# MB9AF15xR register map
File version: 1.7
Registers are 32-bit, read-write, reset 0x0 unless marked. A register's access mark holds for its fields unless they carry their own. Offsets are from the block's base; [hi:lo] are bit positions; {n}, {i} and the like mark numbered series; 'fields as' and 'values as' point back to an identical list.

## GPIO — General-purpose I/O ports
Base 0x40033000
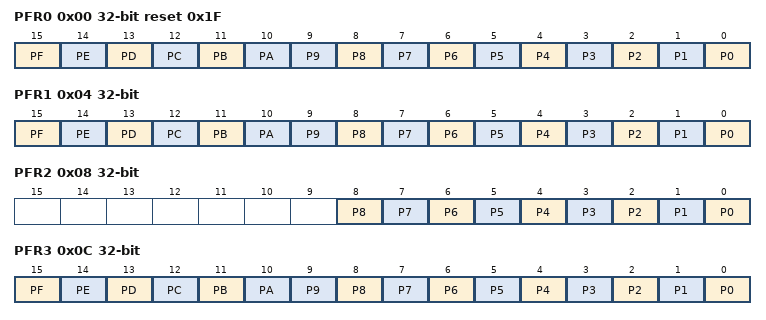
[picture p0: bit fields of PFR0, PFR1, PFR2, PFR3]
0x00 PFR0 reset 0x1F — Port function setting register 0
  [15] PF — Bit15 of PFR0
  [14] PE — Bit14 of PFR0
  [13] PD — Bit13 of PFR0
  [12] PC — Bit12 of PFR0
  [11] PB — Bit11 of PFR0
  [10] PA — Bit10 of PFR0
  [n] P{n} (n=0..9) — Bit{n} of PFR0
0x04 PFR1 — Port function setting register 1
  [15] PF — Bit15 of PFR1
  [14] PE — Bit14 of PFR1
  [13] PD — Bit13 of PFR1
  [12] PC — Bit12 of PFR1
  [11] PB — Bit11 of PFR1
  [10] PA — Bit10 of PFR1
  [n] P{n} (n=0..9) — Bit{n} of PFR1
0x08 PFR2 — Port function setting register 2
  [n] P{n} (n=0..8) — Bit{n} of PFR2
0x0C PFR3 — Port function setting register 3
  [15] PF — Bit15 of PFR3
  [14] PE — Bit14 of PFR3
  [13] PD — Bit13 of PFR3
  [12] PC — Bit12 of PFR3
  [11] PB — Bit11 of PFR3
  [10] PA — Bit10 of PFR3
  [n] P{n} (n=0..9) — Bit{n} of PFR3
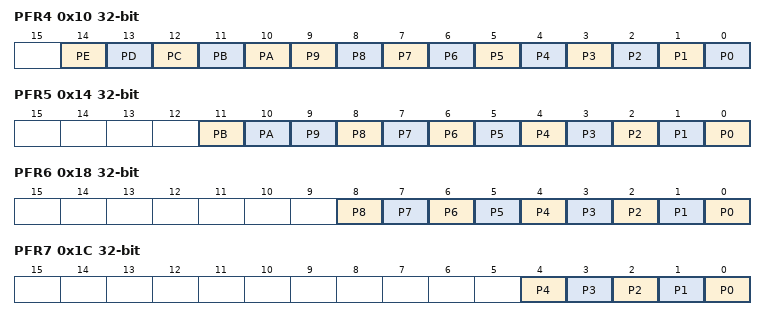
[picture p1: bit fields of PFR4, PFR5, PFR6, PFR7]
0x10 PFR4 — Port function setting register 4
  [14] PE — Bit14 of PFR4
  [13] PD — Bit13 of PFR4
  [12] PC — Bit12 of PFR4
  [11] PB — Bit11 of PFR4
  [10] PA — Bit10 of PFR4
  [n] P{n} (n=0..9) — Bit{n} of PFR4
0x14 PFR5 — Port function setting register 5
  [11] PB — Bit11 of PFR5
  [10] PA — Bit10 of PFR5
  [n] P{n} (n=0..9) — Bit{n} of PFR5
0x18 PFR6 — Port function setting register 6
  [n] P{n} (n=0..8) — Bit{n} of PFR6
0x1C PFR7 — Port function setting register 7
  [n] P{n} (n=0..4) — Bit{n} of PFR6
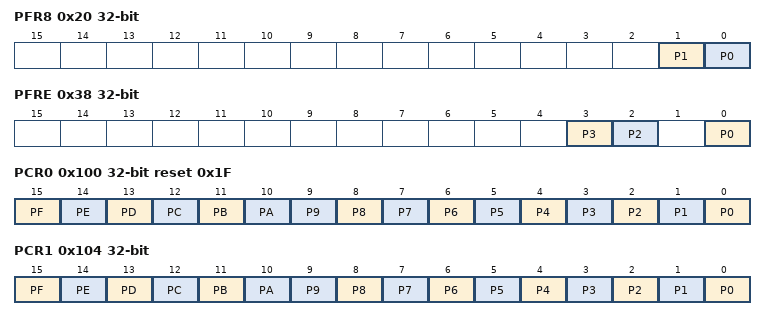
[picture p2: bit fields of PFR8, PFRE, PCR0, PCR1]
0x20 PFR8 — Port function setting register 8
  [1] P1 — Bit1 of PFR8
  [0] P0 — Bit0 of PFR8
0x38 PFRE — Port function setting register E
  [3] P3 — Bit3 of PFRE
  [2] P2 — Bit2 of PFRE
  [0] P0 — Bit0 of PFRE
0x100 PCR0 reset 0x1F — Pull-up Setting Register 0
  fields as PFR0
0x104 PCR1 — Pull-up Setting Register 1
  fields as PFR1
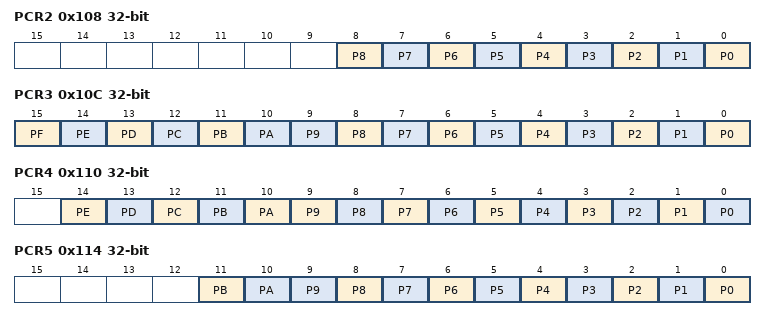
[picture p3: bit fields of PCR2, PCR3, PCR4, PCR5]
0x108 PCR2 — Pull-up Setting Register 2
  [n] P{n} (n=0..8) — Bit{n} of PFR2
0x10C PCR3 — Pull-up Setting Register 3
  fields as PFR3
0x110 PCR4 — Pull-up Setting Register 4
  fields as PFR4
0x114 PCR5 — Pull-up Setting Register 5
  fields as PFR5
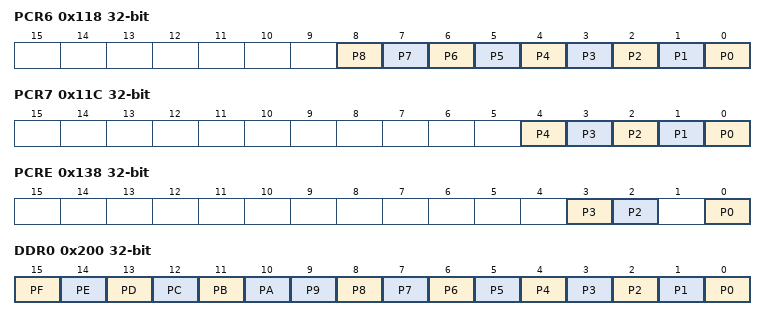
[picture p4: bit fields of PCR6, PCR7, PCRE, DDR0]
0x118 PCR6 — Pull-up Setting Register 6
  [n] P{n} (n=0..8) — Bit{n} of PFR6
0x11C PCR7 — Pull-up Setting Register 7
  [n] P{n} (n=0..4) — Bit{n} of PFR6
0x138 PCRE — Pull-up Setting Register E
  fields as PFRE
0x200 DDR0 — Port input/output direction setting register 0
  [15] PF — Bit15 of DDR0
  [14] PE — Bit14 of DDR0
  [13] PD — Bit13 of DDR0
  [12] PC — Bit12 of DDR0
  [11] PB — Bit11 of DDR0
  [10] PA — Bit10 of DDR0
  [n] P{n} (n=0..9) — Bit{n} of DDR0
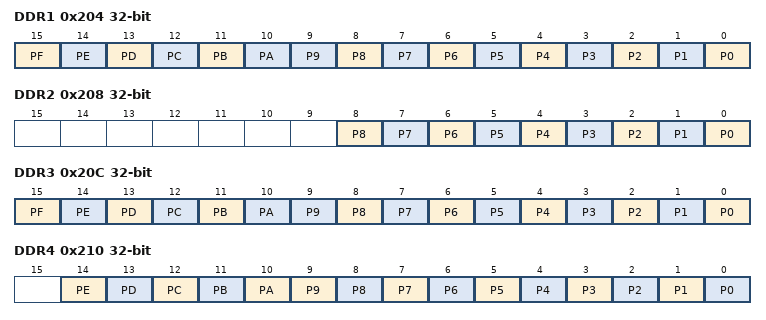
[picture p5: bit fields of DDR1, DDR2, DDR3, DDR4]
0x204 DDR1 — Port input/output direction setting register 1
  fields as PFR1
0x208 DDR2 — Port input/output direction setting register 2
  [n] P{n} (n=0..8) — Bit{n} of PFR2
0x20C DDR3 — Port input/output direction setting register 3
  fields as PFR3
0x210 DDR4 — Port input/output direction setting register 4
  fields as PFR4
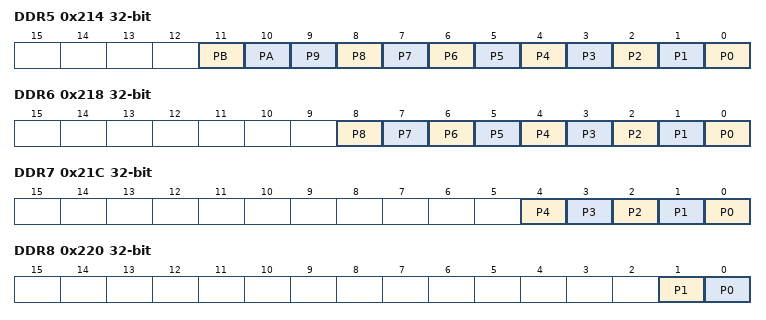
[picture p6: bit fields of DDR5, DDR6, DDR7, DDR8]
0x214 DDR5 — Port input/output direction setting register 5
  fields as PFR5
0x218 DDR6 — Port input/output direction setting register 6
  [n] P{n} (n=0..8) — Bit{n} of PFR6
0x21C DDR7 — Port input/output direction setting register 7
  [n] P{n} (n=0..4) — Bit{n} of PFR6
0x220 DDR8 — Port input/output direction setting register 8
  [1] P1 — Bit1 of PFR8
  [0] P0 — Bit0 of PFR8
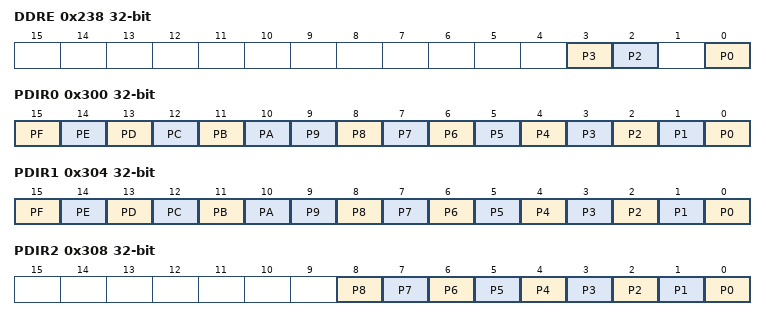
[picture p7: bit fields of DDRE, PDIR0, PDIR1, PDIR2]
0x238 DDRE — Port input/output direction setting register E
  fields as PFRE
0x300 PDIR0 — Port input data register 0
  fields as DDR0
0x304 PDIR1 — Port input data register 1
  fields as PFR1
0x308 PDIR2 — Port input data register 2
  [n] P{n} (n=0..8) — Bit{n} of PFR2
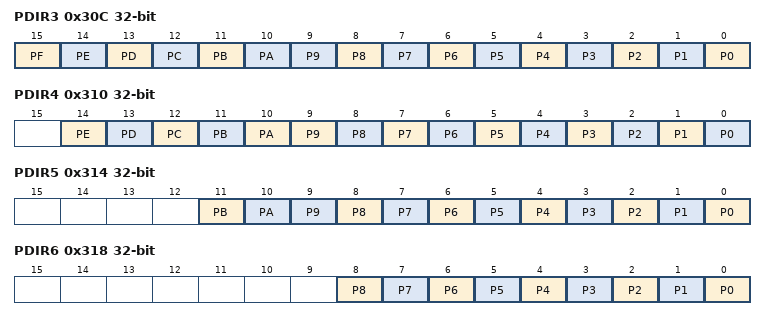
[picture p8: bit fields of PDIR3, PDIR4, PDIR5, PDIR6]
0x30C PDIR3 — Port input data register 3
  fields as PFR3
0x310 PDIR4 — Port input data register 4
  fields as PFR4
0x314 PDIR5 — Port input data register 5
  fields as PFR5
0x318 PDIR6 — Port input data register 6
  [n] P{n} (n=0..8) — Bit{n} of PFR6
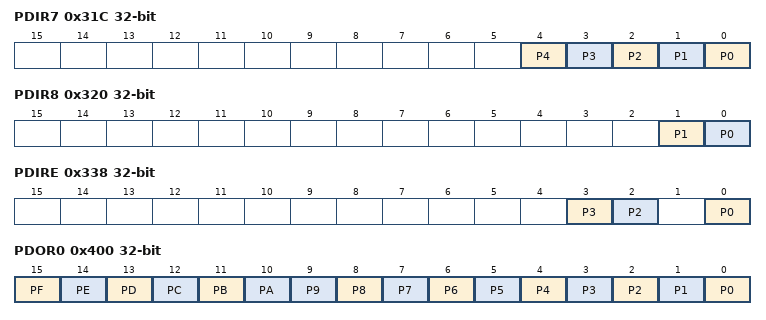
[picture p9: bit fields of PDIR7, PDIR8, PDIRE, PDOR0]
0x31C PDIR7 — Port input data register 7
  [n] P{n} (n=0..4) — Bit{n} of PFR6
0x320 PDIR8 — Port input data register 8
  [1] P1 — Bit1 of PFR8
  [0] P0 — Bit0 of PFR8
0x338 PDIRE — Port input data register E
  fields as PFRE
0x400 PDOR0 — Port output data register 0
  fields as DDR0
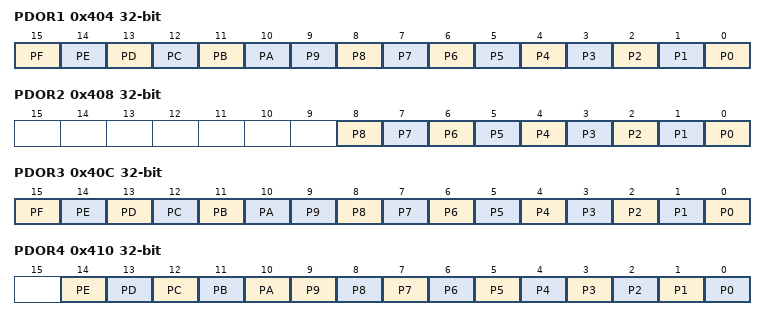
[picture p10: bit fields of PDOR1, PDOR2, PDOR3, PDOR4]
0x404 PDOR1 — Port output data register 1
  fields as PFR1
0x408 PDOR2 — Port output data register 2
  [n] P{n} (n=0..8) — Bit{n} of PFR2
0x40C PDOR3 — Port output data register 3
  fields as PFR3
0x410 PDOR4 — Port output data register 4
  fields as PFR4
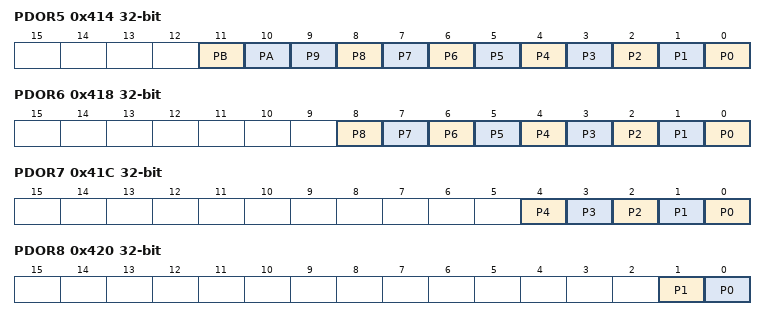
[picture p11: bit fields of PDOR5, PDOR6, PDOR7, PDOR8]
0x414 PDOR5 — Port output data register 5
  fields as PFR5
0x418 PDOR6 — Port output data register 6
  [n] P{n} (n=0..8) — Bit{n} of PFR6
0x41C PDOR7 — Port output data register 7
  [n] P{n} (n=0..4) — Bit{n} of PFR6
0x420 PDOR8 — Port output data register 8
  [1] P1 — Bit1 of PFR8
  [0] P0 — Bit0 of PFR8
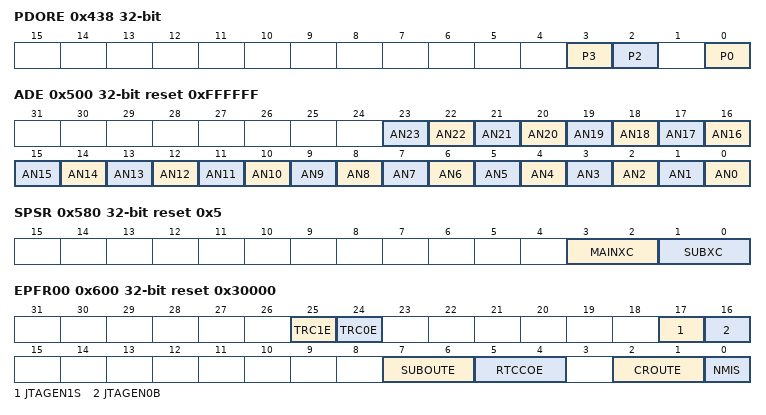
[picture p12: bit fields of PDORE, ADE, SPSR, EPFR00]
0x438 PDORE — Port output data register E
  fields as PFRE
0x500 ADE reset 0xFFFFFF — Analog input setting register
  [n] AN{n} (n=0..23) — Bit{n} of ADE
0x580 SPSR reset 0x5 — Special port setting register
  [3:2] MAINXC — Main clock(oscillation) pin setting bit
  [1:0] SUBXC — Sub clock(oscillation) pin setting bit
0x600 EPFR00 reset 0x30000 — Extended pin function setting register 00
  [25] TRC1E — TRACED function select bit1
  [24] TRC0E — TRACED function select bit0
  [17] JTAGEN1S — JTAG function select bit1
  [16] JTAGEN0B — JTAG function select bit0
  [7:6] SUBOUTE — Sub clock divide output function select bit
  [5:4] RTCCOE — RTC clock output select bit
  [2:1] CROUTE — Internal high-speed CR oscillation output function select bit
  [0] NMIS — NMIX function select bit
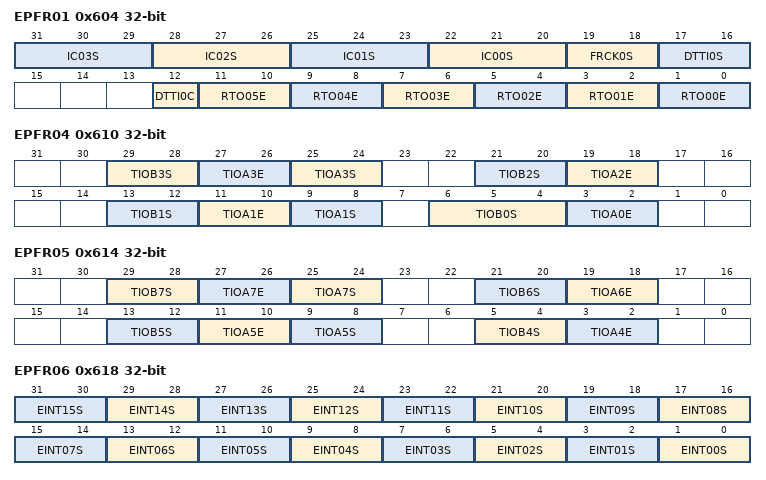
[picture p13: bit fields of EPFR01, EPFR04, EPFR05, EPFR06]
0x604 EPFR01 — Extended pin function setting register 01
  [3n+22:3n+20] IC{n:02}S (n=0..3) — IC{n:02} input select bit
  [19:18] FRCK0S — FRCK0 input select bit
  [17:16] DTTI0S — DTTIX0 input select bit
  [12] DTTI0C — DTTIX0 function select bit
  [2n+1:2n] RTO{n:02}E (n=0..5) — RTO{n:02}E output select bit
0x610 EPFR04 — Extended pin function setting register 04
  [29:28] TIOB3S — TIOB3 input select bit
  [27:26] TIOA3E — TIOA3E output select bit
  [25:24] TIOA3S — TIOA3 input select bit
  [21:20] TIOB2S — TIOB2 input select bit
  [19:18] TIOA2E — TIOA2 output select bit
  [13:12] TIOB1S — TIOB1 input select bit
  [11:10] TIOA1E — TIOA1E output select bit
  [9:8] TIOA1S — TIOA1 input select bit
  [6:4] TIOB0S — TIOB0 input select bit
  [3:2] TIOA0E — TIOA0 output select bit
0x614 EPFR05 — Extended pin function setting register 05
  [29:28] TIOB7S — TIOB7 input select Bit
  [27:26] TIOA7E — TIOA7E output select bit
  [25:24] TIOA7S — TIOA7 input select bit
  [21:20] TIOB6S — TIOB6 input select bit
  [19:18] TIOA6E — TIOA6 output select bit
  [13:12] TIOB5S — TIOB5 input select bit
  [11:10] TIOA5E — TIOA5E output select bit
  [9:8] TIOA5S — TIOA5 input select bit
  [5:4] TIOB4S — TIOB4 input select bit
  [3:2] TIOA4E — TIOA4 output select bit
0x618 EPFR06 — Extended pin function setting register 06
  [2n+1:2n] EINT{n:02}S (n=0..15) — External interrupt {n} input select bit
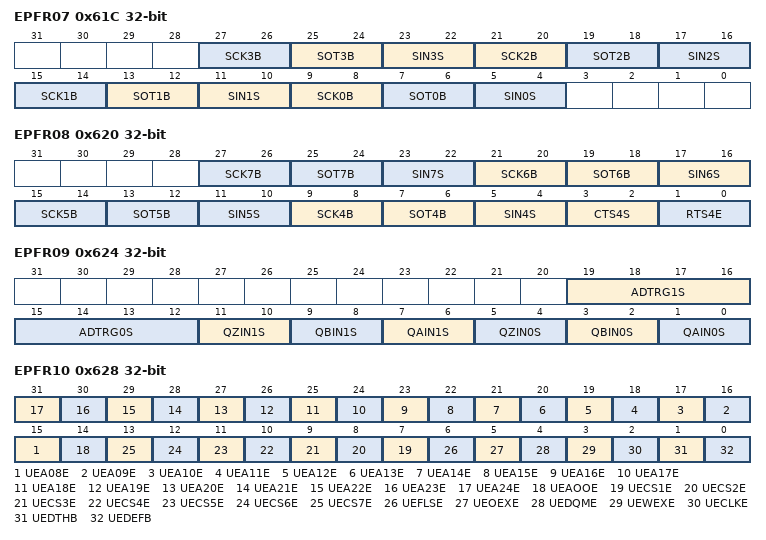
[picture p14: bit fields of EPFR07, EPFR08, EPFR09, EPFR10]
0x61C EPFR07 — Extended pin function setting register 07
  [6n+9:6n+8] SCK{n}B (n=0..3) — SCK{n} input/output select bit
  [25:24] SOT3B — SOT3B input/output select bit
  [6n+5:6n+4] SIN{n}S (n=0..3) — SIN{n}S input select bit
  [19:18] SOT2B — SOT2B input/output select bit
  [13:12] SOT1B — SCK1B input/output select bit
  [7:6] SOT0B — SOT0B input/output select bit
0x620 EPFR08 — Extended pin function setting register 08
  [6n-15:6n-16] SCK{n}B (n=4..7) — SCK{n} input/output select bit
  [6n-17:6n-18] SOT{n}B (n=4..7) — SOT{n}B input/output select bit
  [6n-19:6n-20] SIN{n}S (n=4..7) — SIN{n}S input select bit
  [3:2] CTS4S — CTS4S input select bit
  [1:0] RTS4E — RTS4E output select bit
0x624 EPFR09 — Extended pin function setting register 09
  [19:16] ADTRG1S — ADTRG1 input select bit
  [15:12] ADTRG0S — ADTRG0 input select bit
  [11:10] QZIN1S — QZIN1S input select bit
  [9:8] QBIN1S — QBIN1S input select bit
  [7:6] QAIN1S — QAIN1S input select bit
  [5:4] QZIN0S — QZIN0S input select bit
  [3:2] QBIN0S — QBIN0S input select bit
  [1:0] QAIN0S — QAIN0S input select bit
0x628 EPFR10 — Extended pin function setting register 10
  [n+7] UEA{n:02}E (n=8..24) — UEA{n:02}E output select bit
  [14] UEAOOE — UEAOOE output select bit
  [n+6] UECS{n}E (n=1..7) — UECS{n}E output select bit
  [6] UEFLSE — UEFLSE output select bit
  [5] UEOEXE — UEOEXE output select bit
  [4] UEDQME — UEDQME output select bit
  [3] UEWEXE — UEWEXE output select bit
  [2] UECLKE — UECLKE output select bit
  [1] UEDTHB — UEDTHB input/output select bit
  [0] UEDEFB — UEDEFB input/output select bit
0x62C EPFR11 — Extended pin function setting register 11
  [25] UERLC — UERLC relocation select bit
  [24] UED15B — UED15B input/output select bit
  [n+9] UED{n:02}B (n=0..14) — UED{n:02}B output select bit
  [n+1] UEA{n:02}E (n=1..7) — UEA{n:02}E output select bit
  [1] UECS0E — UECS0E output select bit
  [0] UEALEE — UEALEE output select bit
0x630 EPFR12 — Extended pin function setting register 12
  [8n-59:8n-60] TIOB{n}S (n=8..11) — TIOB{n} Input Select bits
  [8n-61:8n-62] TIOA{n}E (n=8..11) — TIOA{n} Output Select bits
  [25:24] TIOA11S — TIOA11 Input Select bits
  [9:8] TIOA9S — TIOA9 Input Select bits
0x634 EPFR13 — Extended pin function setting register 13
  [8n-91:8n-92] TIOB{n}S (n=12..15) — TIOB{n} Input Select bits
  [8n-93:8n-94] TIOA{n}E (n=12..15) — TIOA{n} Output Select bits
  [25:24] TIOA15S — TIOA15 Input Select bits
  [9:8] TIOA13S — TIOA13 Input Select bits
0x63C EPFR15 — Extended pin function setting register 15
  [2n-31:2n-32] EINT{n}S (n=16..23) — External interrupt {n} input select bit
0x640 EPFR16 — Extended pin function setting register 16
  [6n-39:6n-40] SCK{n}B (n=8..11) — SCK{n} input/output select bit
  [25:24] SOT11B — SOT11B input/output select bit
  [6n-43:6n-44] SIN{n}S (n=8..11) — SIN{n}S input select bit
  [19:18] SOT10B — SOT10B input/output select bit
  [13:12] SOT9B — SCK9B input/output select bit
  [7:6] SOT8B — SOT8B input/output select bit
0x644 EPFR17 — Extended pin function setting register 17
  [6n-63:6n-64] SCK{n}B (n=12..15) — SCK{n-8} input/output select bit
  [6n-65:6n-66] SOT{n}B (n=12..15) — SOT{n-8}B input/output select bit
  [6n-67:6n-68] SIN{n}S (n=12..15) — SIN{n-8}S input select bit
0x648 EPFR18 — Extended pin function setting register 18
  [3:2] CECR1B — CEC1 Input/Output Select bit
  [1:0] CECR0B — CEC0 Input/Output Select bit
0x700 PZR0 — Port Pseudo Open Drain Setting Register 0
  [12] PC — Bit12 of PZR0
  [11] PB — Bit11 of PZR0
  [10] PA — Bit10 of PZR0
0x710 PZR4 — Port Pseudo Open Drain Setting Register 4
  [14] PE — Bit14 of PZR4
  [13] PD — Bit13 of PZR4
  [12] PC — Bit12 of PZR4
0x714 PZR5 — Port Pseudo Open Drain Setting Register 5
  [8] P8 — Bit8 of PZR5
  [7] P7 — Bit7 of PZR5
  [6] P6 — Bit6 of PZR5
0x718 PZR6 — Port Pseudo Open Drain Setting Register 6
  [0] P0 — Bit0 of PZR6

## Notices in the file
Licence Terms
FUJITSU SEMICONDUCTOR LIMITED (gLICENSORh) hereby grants and
you (gLICENSEEh) hereby accept a non transferable, non-exclusive
licence to use and copy the deliverables (gDeliverablesh) solely for
the purpose of; (i) developing LICENSEEfs development tools and
distributing such development tools to third parties; (ii) generating
derivative representations of the Deliverables to develop and debug
software for LICENSORfs targeted devices or device series identified
within the Deliverables, (together the gPurposeh) under the following
terms and conditions:
1. Ownership.
The Deliverables are the property of LICENSOR. LICENSEE acquires no
right, title or interest in the Deliverables other than the licence
rights granted herein.
2. Use.
LICENSEE shall only be permitted to use the Deliverables for the
Purpose. LICENSEE shall not reverse engineer, decompile or
disassemble the Deliverables, in whole or in part.
3. Copies.
All copies of the Deliverables must bear the same notice(s) contained
on the original copies of the Deliverables.
4. No Warranty.
THE DELIVERABLES ARE PROVIDED gAS ISh AND ANY EXPRESS, IMPLIED OR
STATUTORY WARRANTIES, INCLUDING, BUT NOT LIMITED TO, THE IMPLIED
WARRANTIES OF MERCHANTABILITY, SATISFACTORY QUALITY AND FITNESS FOR
A PARTICULAR PURPOSE ARE DISCLAIMED.
IN NO EVENT SHALL LICENSOR BE LIABLE FOR ANY DIRECT, INDIRECT,
INCIDENTAL, SPECIAL, EXEMPLARY, OR CONSEQUENTIAL DAMAGES HOWEVER CAUSED
AND ON ANY THEORY OF LIABILITY, WHETHER IN CONTRACT, STRICT LIABILITY,
OR TORT (INCLUDING NEGLIGENCE OR OTHERWISE) ARISING IN ANY WAY OUT OF
THE USE OF THE DELIVERABLES, EVEN IF ADVISED OF THE POSSIBILITY OF SUCH
DAMAGE.
LICENSEE EXPRESSLY ASSUMES ALL LIABILITIES AND RISKS, FOR USE OR
OPERATION OF THE DELIVERABLES.
5.In the event that LICENSEE receives early access to the Deliverables,
LICENSEE acknowledges and agrees that;
(a) notwithstanding the licence grants above, LICENSEE shall only be
permitted to use the Deliverables solely internally for evaluation and
providing feedback to LICENSOR;
(b) except with respect to the limited licence grants in 5(a), LICENSEE
shall be subject to all of the terms and conditions set out above; and
(c) the Deliverables are confidential information and LICENSEE shall
maintain in confidence the Deliverables and apply security measures no
less stringent than the measures that LICENSEE applies to its own like
information, but not less than a reasonable degree of care, to prevent
unauthorised disclosure and use of the Deliverables.
